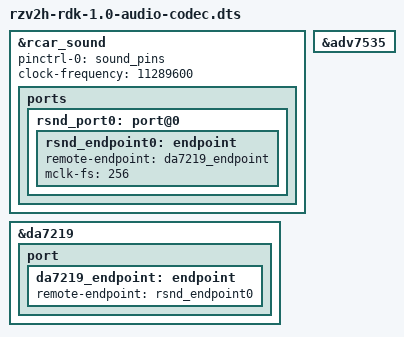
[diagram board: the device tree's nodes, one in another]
// SPDX-License-Identifier: GPL-2.0+
/*
 * Device Tree Overlay for RZ/V2H RDK DA7219 Codec Audio
 *
 * Copyright (C) 2025 Renesas Electronics Corporation
 */

/dts-v1/;
/plugin/;

#include <dt-bindings/pinctrl/rzv2h-pinctrl.h>

/ {
    fragment@0 {
        target = <&rcar_sound>;
        __overlay__ {
            pinctrl-0 = <&sound_pins>;
            clock-frequency = <11289600>;

            ports {
                rsnd_port0: port@0 {
                    rsnd_endpoint0: endpoint {
                        remote-endpoint = <&da7219_endpoint>;
                        mclk-fs = <256>;
                        // TODO: add record pins
                    };
                };
            };
        };
    };

    fragment@1 {
        target = <&adv7535>;
        __overlay__ {
            /* Remove HDMI audio capability */
            /delete-property/ #sound-dai-cells;
            /delete-node/ port@2;
        };
    };

    fragment@2 {
        target = <&da7219>;
        __overlay__ {
            status = "okay";

            port {
                da7219_endpoint: endpoint {
                    remote-endpoint = <&rsnd_endpoint0>;
                };
            };
        };
    };
};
